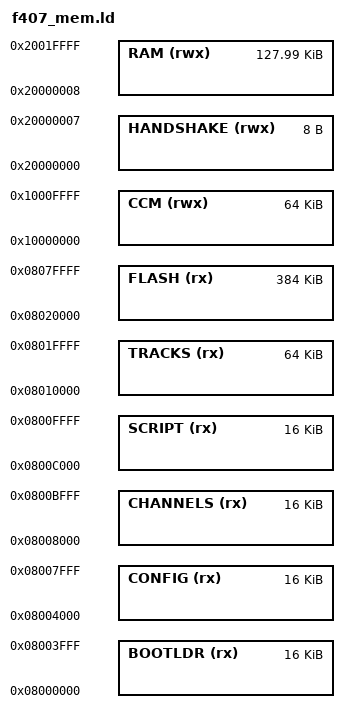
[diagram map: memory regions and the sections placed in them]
_estack = 0x20020000;

_Min_Heap_Size = 0x200;
_Min_Stack_Size = 0x200;

MEMORY
{
  BOOTLDR  	(rx) 	: ORIGIN = 0x08000000, LENGTH = 16K
  CONFIG 	(rx) 	: ORIGIN = 0x08004000, LENGTH = 16K
  CHANNELS 	(rx) 	: ORIGIN = 0x08008000, LENGTH = 16K
  SCRIPT 	(rx) 	: ORIGIN = 0x0800C000, LENGTH = 16K
  TRACKS 	(rx) 	: ORIGIN = 0x08010000, LENGTH = 64K  
  FLASH 	(rx) 	: ORIGIN = 0x08020000, LENGTH = 384K
  HANDSHAKE     (rwx)   : ORIGIN = 0x20000000, LENGTH = 8
  RAM 		(rwx) 	: ORIGIN = 0x20000008, LENGTH = 131064
  CCM 		(rwx) 	: ORIGIN = 0x10000000, LENGTH = 64K
}

_heap_address = ORIGIN(RAM);
_CONFIG_HEAP_SIZE = LENGTH(RAM);
_flash_start = ORIGIN(FLASH) - ORIGIN(BOOTLDR);

